# jbr_1986BE9x register map
Registers are 32-bit, access not given, no defined reset value unless marked. A register's access mark holds for its fields unless they carry their own. Addresses are absolute; registers are grouped by the start of their names; [hi:lo] are bit positions; {n}, {i} and the like mark numbered series.

## GPIOA
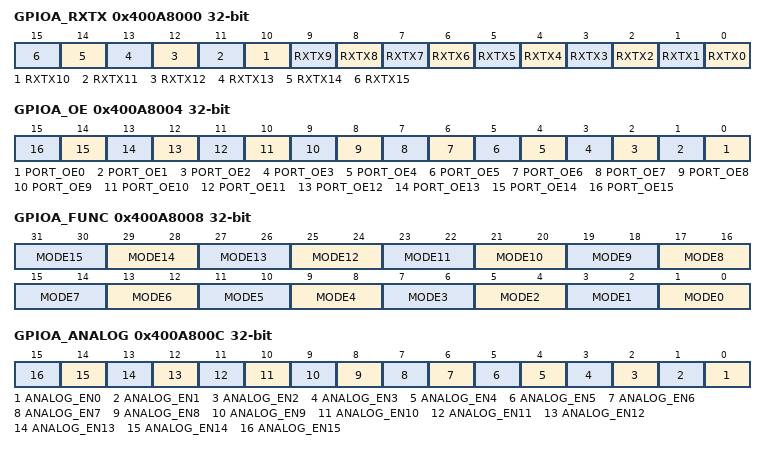
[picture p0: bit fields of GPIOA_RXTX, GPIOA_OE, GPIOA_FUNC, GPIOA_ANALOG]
0x400A8000 GPIOA_RXTX
  [n] RXTX{n} (n=0..15)
0x400A8004 GPIOA_OE
  [n] PORT_OE{n} (n=0..15)
0x400A8008 GPIOA_FUNC
  [2n+1:2n] MODE{n} (n=0..15)
0x400A800C GPIOA_ANALOG
  [n] ANALOG_EN{n} (n=0..15)
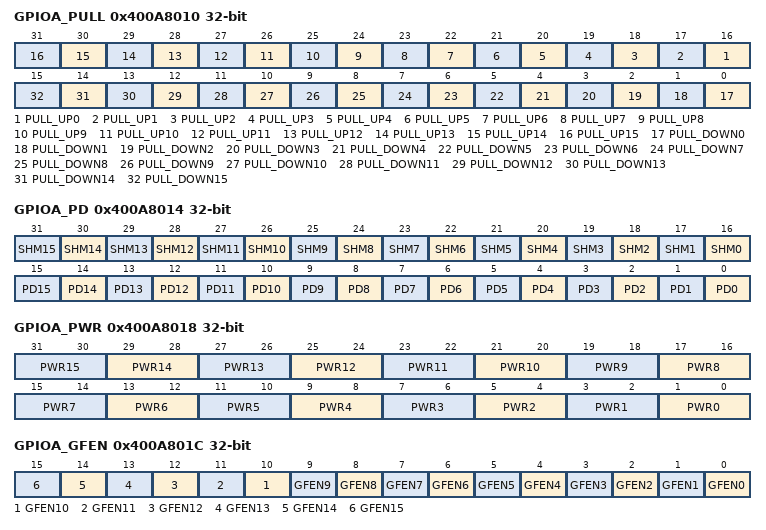
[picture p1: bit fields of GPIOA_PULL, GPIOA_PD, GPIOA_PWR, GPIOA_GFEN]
0x400A8010 GPIOA_PULL
  [n+16] PULL_UP{n} (n=0..15), [n] PULL_DOWN{n} (n=0..15)
0x400A8014 GPIOA_PD
  [n+16] SHM{n} (n=0..15), [n] PD{n} (n=0..15)
0x400A8018 GPIOA_PWR
  [2n+1:2n] PWR{n} (n=0..15)
0x400A801C GPIOA_GFEN
  [n] GFEN{n} (n=0..15)

## GPIOB
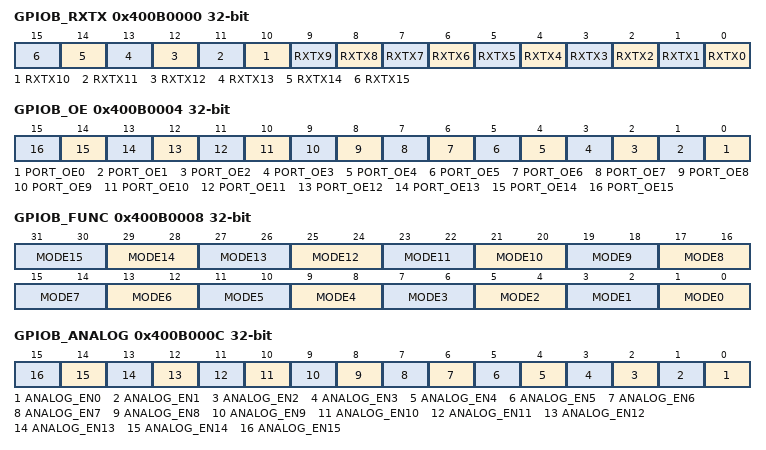
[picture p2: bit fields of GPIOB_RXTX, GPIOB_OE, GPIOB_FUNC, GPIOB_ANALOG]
0x400B0000 GPIOB_RXTX
  [n] RXTX{n} (n=0..15)
0x400B0004 GPIOB_OE
  [n] PORT_OE{n} (n=0..15)
0x400B0008 GPIOB_FUNC
  [2n+1:2n] MODE{n} (n=0..15)
0x400B000C GPIOB_ANALOG
  [n] ANALOG_EN{n} (n=0..15)
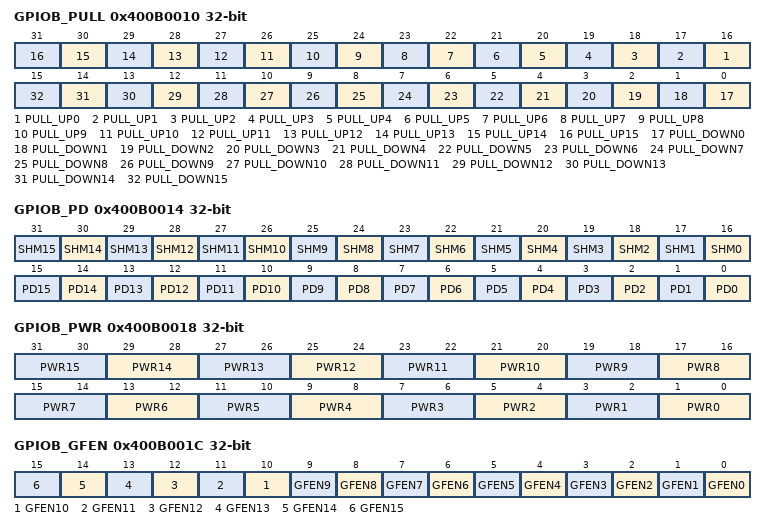
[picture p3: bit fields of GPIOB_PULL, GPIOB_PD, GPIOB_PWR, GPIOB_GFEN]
0x400B0010 GPIOB_PULL
  [n+16] PULL_UP{n} (n=0..15), [n] PULL_DOWN{n} (n=0..15)
0x400B0014 GPIOB_PD
  [n+16] SHM{n} (n=0..15), [n] PD{n} (n=0..15)
0x400B0018 GPIOB_PWR
  [2n+1:2n] PWR{n} (n=0..15)
0x400B001C GPIOB_GFEN
  [n] GFEN{n} (n=0..15)

## GPIOD
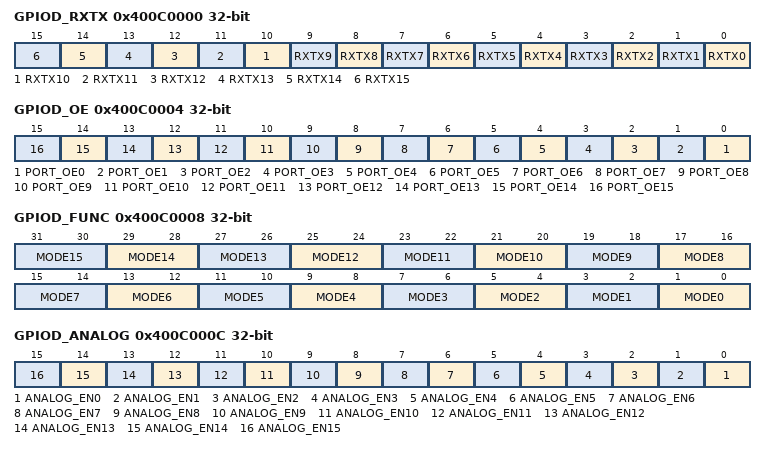
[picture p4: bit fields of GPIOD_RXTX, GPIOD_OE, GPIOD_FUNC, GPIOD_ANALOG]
0x400C0000 GPIOD_RXTX
  [n] RXTX{n} (n=0..15)
0x400C0004 GPIOD_OE
  [n] PORT_OE{n} (n=0..15)
0x400C0008 GPIOD_FUNC
  [2n+1:2n] MODE{n} (n=0..15)
0x400C000C GPIOD_ANALOG
  [n] ANALOG_EN{n} (n=0..15)
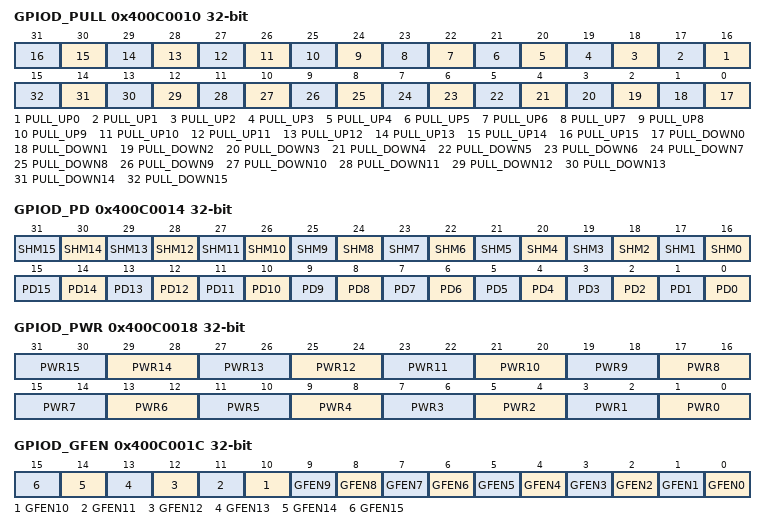
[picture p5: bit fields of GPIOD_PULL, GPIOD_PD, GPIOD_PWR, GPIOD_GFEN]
0x400C0010 GPIOD_PULL
  [n+16] PULL_UP{n} (n=0..15), [n] PULL_DOWN{n} (n=0..15)
0x400C0014 GPIOD_PD
  [n+16] SHM{n} (n=0..15), [n] PD{n} (n=0..15)
0x400C0018 GPIOD_PWR
  [2n+1:2n] PWR{n} (n=0..15)
0x400C001C GPIOD_GFEN
  [n] GFEN{n} (n=0..15)

## GPIOE
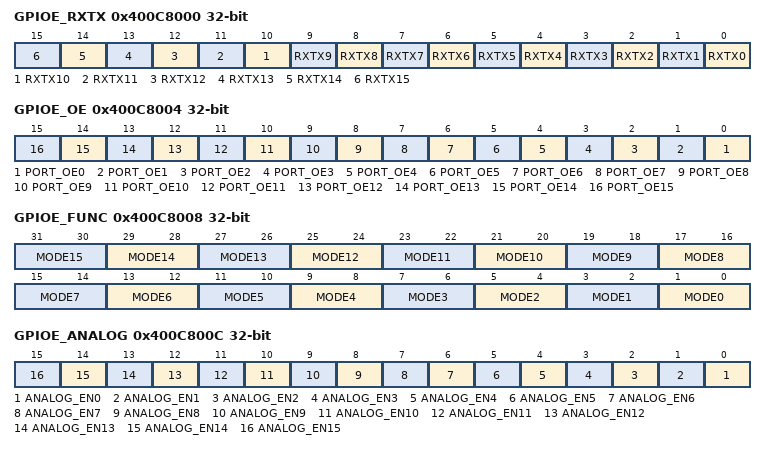
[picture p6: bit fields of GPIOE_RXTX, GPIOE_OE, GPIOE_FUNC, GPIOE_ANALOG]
0x400C8000 GPIOE_RXTX
  [n] RXTX{n} (n=0..15)
0x400C8004 GPIOE_OE
  [n] PORT_OE{n} (n=0..15)
0x400C8008 GPIOE_FUNC
  [2n+1:2n] MODE{n} (n=0..15)
0x400C800C GPIOE_ANALOG
  [n] ANALOG_EN{n} (n=0..15)
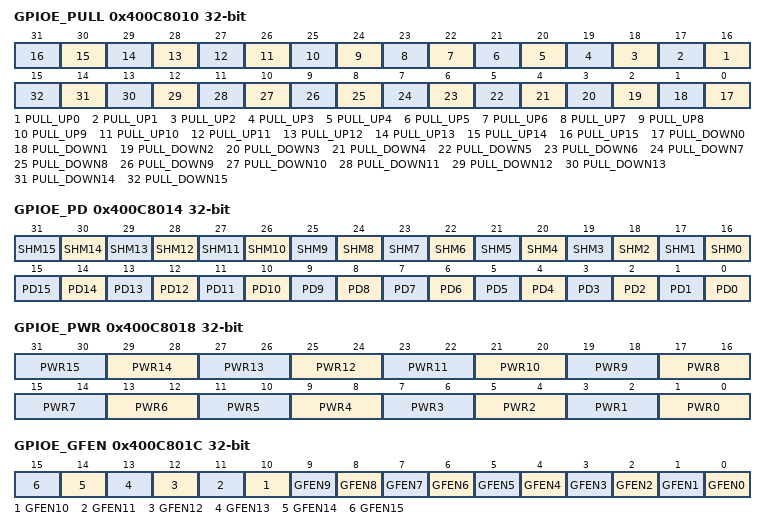
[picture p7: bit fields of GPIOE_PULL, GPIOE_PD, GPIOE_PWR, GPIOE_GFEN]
0x400C8010 GPIOE_PULL
  [n+16] PULL_UP{n} (n=0..15), [n] PULL_DOWN{n} (n=0..15)
0x400C8014 GPIOE_PD
  [n+16] SHM{n} (n=0..15), [n] PD{n} (n=0..15)
0x400C8018 GPIOE_PWR
  [2n+1:2n] PWR{n} (n=0..15)
0x400C801C GPIOE_GFEN
  [n] GFEN{n} (n=0..15)

## GPIOF
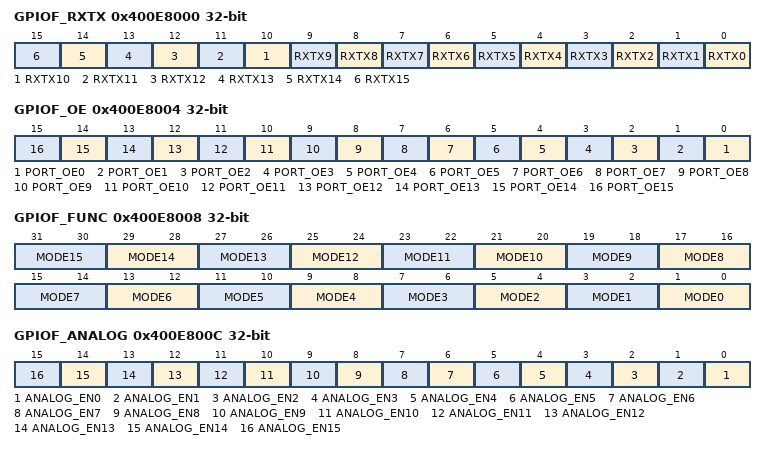
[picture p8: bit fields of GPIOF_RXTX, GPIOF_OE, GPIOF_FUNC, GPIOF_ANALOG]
0x400E8000 GPIOF_RXTX
  [n] RXTX{n} (n=0..15)
0x400E8004 GPIOF_OE
  [n] PORT_OE{n} (n=0..15)
0x400E8008 GPIOF_FUNC
  [2n+1:2n] MODE{n} (n=0..15)
0x400E800C GPIOF_ANALOG
  [n] ANALOG_EN{n} (n=0..15)
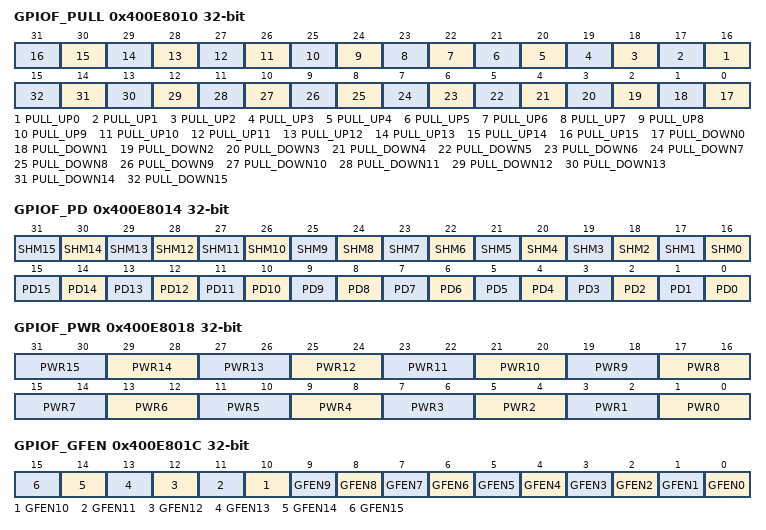
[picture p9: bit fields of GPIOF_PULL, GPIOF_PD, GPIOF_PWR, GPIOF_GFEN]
0x400E8010 GPIOF_PULL
  [n+16] PULL_UP{n} (n=0..15), [n] PULL_DOWN{n} (n=0..15)
0x400E8014 GPIOF_PD
  [n+16] SHM{n} (n=0..15), [n] PD{n} (n=0..15)
0x400E8018 GPIOF_PWR
  [2n+1:2n] PWR{n} (n=0..15)
0x400E801C GPIOF_GFEN
  [n] GFEN{n} (n=0..15)

## DMA
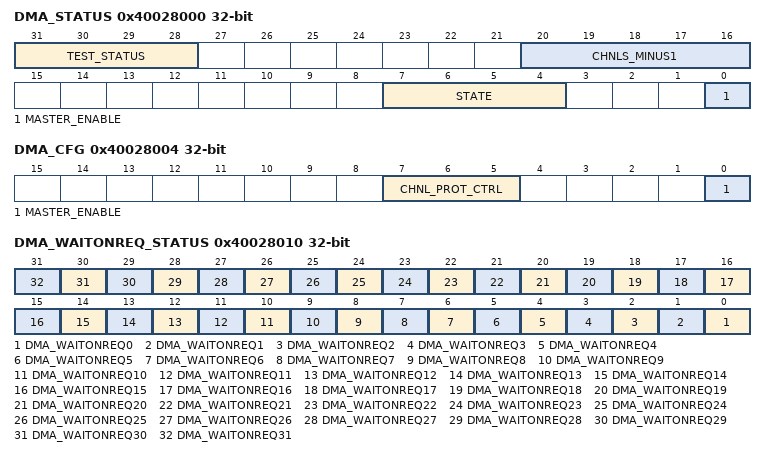
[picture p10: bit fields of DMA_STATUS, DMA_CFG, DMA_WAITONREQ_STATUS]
0x40028000 DMA_STATUS
  [31:28] TEST_STATUS, [20:16] CHNLS_MINUS1, [7:4] STATE, [0] MASTER_ENABLE
0x40028004 DMA_CFG
  [7:5] CHNL_PROT_CTRL, [0] MASTER_ENABLE
0x40028010 DMA_WAITONREQ_STATUS
  [n] DMA_WAITONREQ{n} (n=0..31)

## CHNL
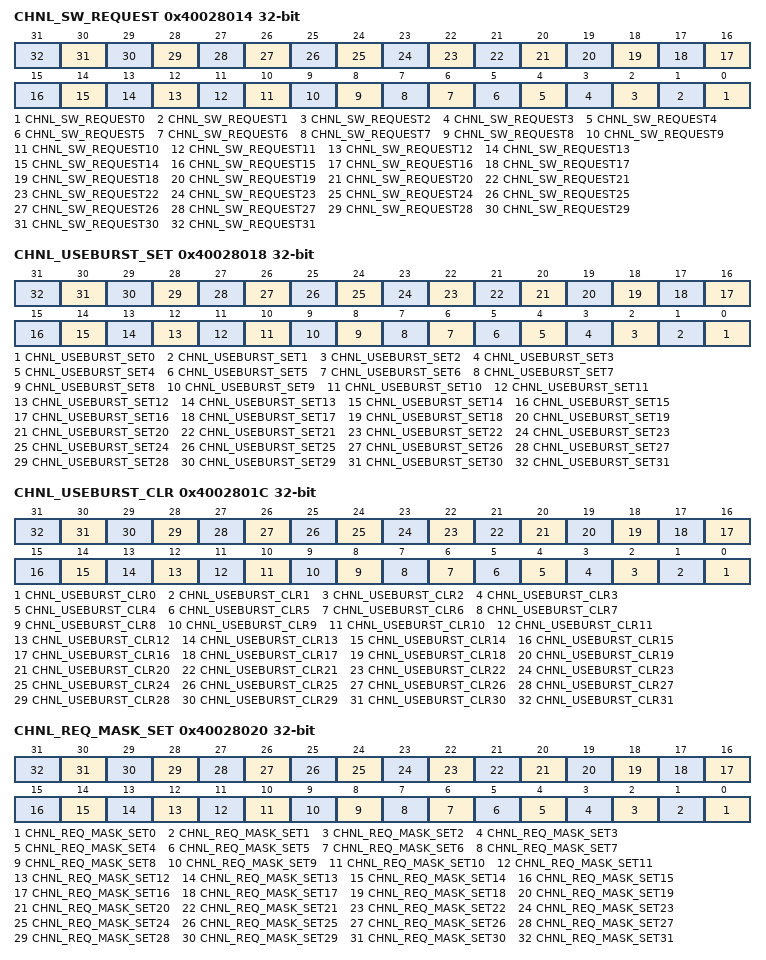
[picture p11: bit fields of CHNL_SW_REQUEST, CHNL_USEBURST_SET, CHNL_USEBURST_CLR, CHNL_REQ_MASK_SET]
0x40028014 CHNL_SW_REQUEST
  [n] CHNL_SW_REQUEST{n} (n=0..31)
0x40028018 CHNL_USEBURST_SET
  [n] CHNL_USEBURST_SET{n} (n=0..31)
0x4002801C CHNL_USEBURST_CLR
  [n] CHNL_USEBURST_CLR{n} (n=0..31)
0x40028020 CHNL_REQ_MASK_SET
  [n] CHNL_REQ_MASK_SET{n} (n=0..31)
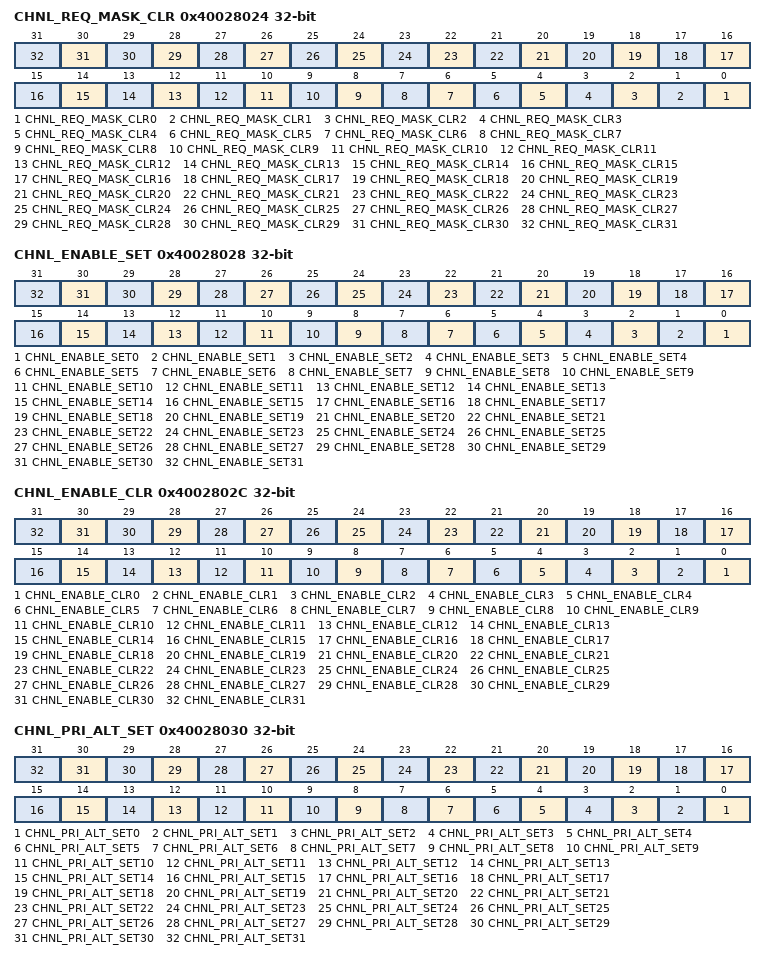
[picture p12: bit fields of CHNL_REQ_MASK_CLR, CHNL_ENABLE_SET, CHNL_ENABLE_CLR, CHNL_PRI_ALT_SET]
0x40028024 CHNL_REQ_MASK_CLR
  [n] CHNL_REQ_MASK_CLR{n} (n=0..31)
0x40028028 CHNL_ENABLE_SET
  [n] CHNL_ENABLE_SET{n} (n=0..31)
0x4002802C CHNL_ENABLE_CLR
  [n] CHNL_ENABLE_CLR{n} (n=0..31)
0x40028030 CHNL_PRI_ALT_SET
  [n] CHNL_PRI_ALT_SET{n} (n=0..31)
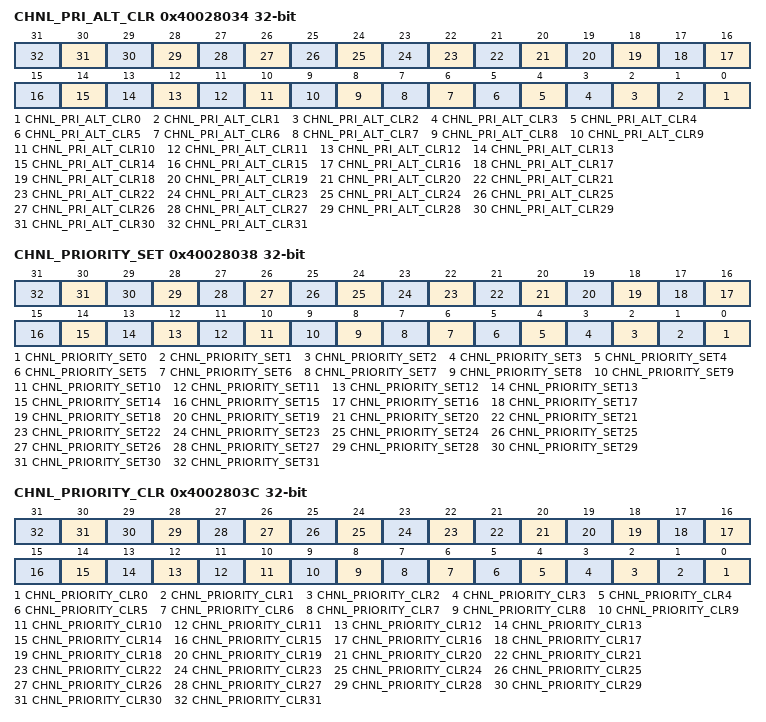
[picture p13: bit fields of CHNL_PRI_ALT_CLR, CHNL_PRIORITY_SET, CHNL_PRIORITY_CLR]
0x40028034 CHNL_PRI_ALT_CLR
  [n] CHNL_PRI_ALT_CLR{n} (n=0..31)
0x40028038 CHNL_PRIORITY_SET
  [n] CHNL_PRIORITY_SET{n} (n=0..31)
0x4002803C CHNL_PRIORITY_CLR
  [n] CHNL_PRIORITY_CLR{n} (n=0..31)

## IWDG
0x40068000 IWDG_KR 16-bit
  [15:0] KEY
0x40068004 IWDG_PR 16-bit
  [2:0] PR
0x40068008 IWDG_RLR 16-bit
  [11:0] RLR
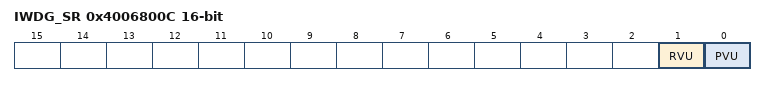
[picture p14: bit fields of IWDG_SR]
0x4006800C IWDG_SR 16-bit
  [1] RVU, [0] PVU

## WWDG
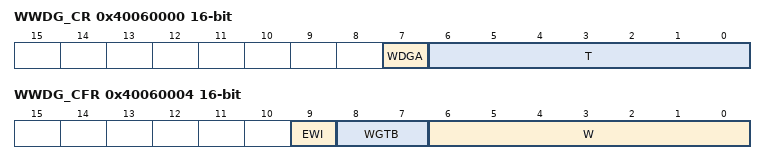
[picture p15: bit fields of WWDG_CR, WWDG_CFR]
0x40060000 WWDG_CR 16-bit
  [7] WDGA, [6:0] T
0x40060004 WWDG_CFR 16-bit
  [9] EWI, [8:7] WGTB, [6:0] W
0x40060008 WWDG_SR 16-bit
  [0] EWIF
